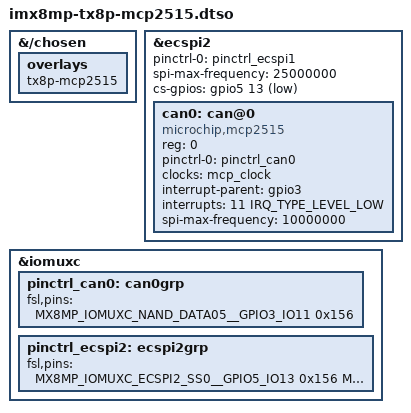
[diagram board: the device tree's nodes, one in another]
// SPDX-License-Identifier: (GPL-2.0 OR MIT)
/*
 * Copyright 2022 Lothar Waßmann <LW@KARO-electronics.de>
 *
 */

/dts-v1/;

/plugin/;

#include <dt-bindings/interrupt-controller/irq.h>
#include <dt-bindings/gpio/gpio.h>
#include "includes/imx8m-karo-mcp2515.dtsi"
#include "imx8mp-pinfunc.h"

&{/chosen} {
	overlays {
		tx8p-mcp2515;
	};
};

&ecspi2 {
	#address-cells = <1>;
	#size-cells = <0>;
	pinctrl-names = "default";
	pinctrl-0 = <&pinctrl_ecspi1>;
	spi-max-frequency = <25000000>;
	cs-gpios = <&gpio5 13 GPIO_ACTIVE_LOW>;
	status = "okay";

	can0: can@0 {
		compatible = "microchip,mcp2515";
		reg = <0>;
		pinctrl-names = "default";
		pinctrl-0 = <&pinctrl_can0>;
		clocks = <&mcp_clock>;
		interrupt-parent = <&gpio3>;
		interrupts = <11 IRQ_TYPE_LEVEL_LOW>;
		spi-max-frequency = <10000000>;
	};
};

&iomuxc {
	pinctrl_can0: can0grp {
		fsl,pins = <
			MX8MP_IOMUXC_NAND_DATA05__GPIO3_IO11	0x156
		>;

	};

	pinctrl_ecspi2: ecspi2grp {
		fsl,pins = <
			MX8MP_IOMUXC_ECSPI2_SS0__GPIO5_IO13	0x156
			MX8MP_IOMUXC_ECSPI2_SCLK__ECSPI2_SCLK	0x156
			MX8MP_IOMUXC_ECSPI2_MOSI__ECSPI2_MOSI	0x156
			MX8MP_IOMUXC_ECSPI2_MISO__ECSPI2_MISO	0x156
		>;
	};
};
